# esp8266 register map
File version: 1.0
CPU: Xtensa LX106 1, little endian, no MPU, FPU, 3 interrupt priority bits
Registers are 32-bit, read-write, reset 0x0 unless marked. A register's access mark holds for its fields unless they carry their own. Offsets are from the block's base; lines under a group give offsets from that group; [hi:lo] are bit positions; {n}, {i} and the like mark numbered series; 'fields as' and 'values as' point back to an identical list; <NAME> marks a mode.

## Memory map
0x3FF00000 DPORT size 0xA4
0x3FF00050 EFUSE size 0x80
0x60000000 UART0 size 0x1E0
0x60000100 SPI1 size 0x100
0x60000200 SPI0 size 0x100
0x60000300 GPIO size 0x3A0
0x60000600 TIMER size 0x120
0x60000700 RTC size 0x100
0x60000800 IO_MUX size 0x220
0x60000900 WDT size 0x80
0x60000B00 SLC size 0x400
0x60000E00 I2S size 0x160
0x60000F00 UART1 size 0x1E0

## DPORT
Base 0x3FF00000
0x04 EDGE_INT_ENABLE
  [31:0] Register
0x14 DPORT_CTL
  [0] DPORT_CTL_DOUBLE_CLK

## EFUSE
Base 0x3FF00050
{0x0+4i} EFUSE_DATA{i} (i=0..3)
  [31:0] Register

## GPIO
Base 0x60000300
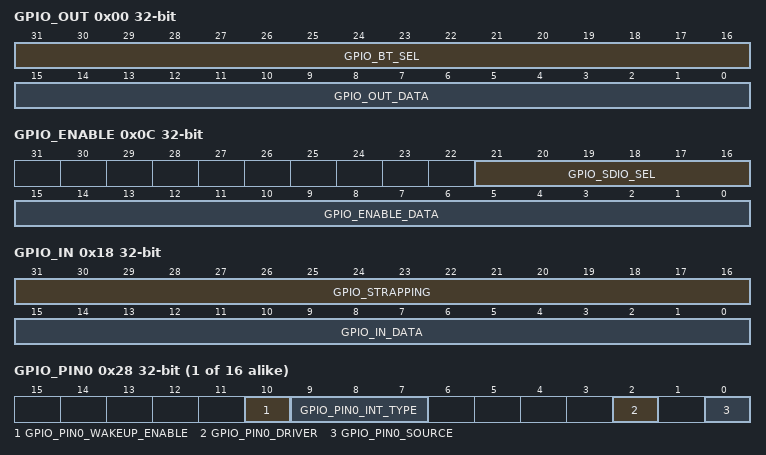
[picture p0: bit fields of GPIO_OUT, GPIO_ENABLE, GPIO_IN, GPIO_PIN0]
0x00 GPIO_OUT — BT-Coexist Selection register
  [31:16] GPIO_BT_SEL — BT-Coexist Selection register
  [15:0] GPIO_OUT_DATA — The output value when the GPIO pin is set as output.
0x04 GPIO_OUT_W1TS wo
  [15:0] GPIO_OUT_DATA_W1TS — Writing 1 into a bit in this register will set the related bit in GPIO_OUT_DATA
0x08 GPIO_OUT_W1TC wo
  [15:0] GPIO_OUT_DATA_W1TC — Writing 1 into a bit in this register will clear the related bit in GPIO_OUT_DATA
0x0C GPIO_ENABLE
  [21:16] GPIO_SDIO_SEL — SDIO-dis selection register
  [15:0] GPIO_ENABLE_DATA — The output enable register.
0x10 GPIO_ENABLE_W1TS wo
  [15:0] GPIO_ENABLE_DATA_W1TS — Writing 1 into a bit in this register will set the related bit in GPIO_ENABLE_DATA
0x14 GPIO_ENABLE_W1TC wo
  [15:0] GPIO_ENABLE_DATA_W1TC — Writing 1 into a bit in this register will clear the related bit in GPIO_ENABLE_DATA
0x18 GPIO_IN — The values of the strapping pins.
  [31:16] GPIO_STRAPPING — The values of the strapping pins.
  [15:0] GPIO_IN_DATA — The values of the GPIO pins when the GPIO pin is set as input.
0x1C GPIO_STATUS
  [15:0] GPIO_STATUS_INTERRUPT — Interrupt enable register.
0x20 GPIO_STATUS_W1TS wo
  [15:0] GPIO_STATUS_INTERRUPT_W1TS — Writing 1 into a bit in this register will set the related bit in GPIO_STATUS_INTERRUPT
0x24 GPIO_STATUS_W1TC wo
  [15:0] GPIO_STATUS_INTERRUPT_W1TC — Writing 1 into a bit in this register will clear the related bit in GPIO_STATUS_INTERRUPT
{0x28+4i} GPIO_PIN{i} (i=0..15)
  [10] GPIO_PIN{i}_WAKEUP_ENABLE — 0: disable; 1: enable GPIO wakeup CPU, only when GPIO_PIN0_INT_TYPE is 0x4 or 0x5
  [9:7] GPIO_PIN{i}_INT_TYPE — 0: disable; 1: positive edge; 2: negative edge; 3: both types of edge; 4: low-level; 5: high-level
  [2] GPIO_PIN{i}_DRIVER — 1: open drain; 0: normal
  [0] GPIO_PIN{i}_SOURCE — 1: sigma-delta; 0: GPIO_DATA
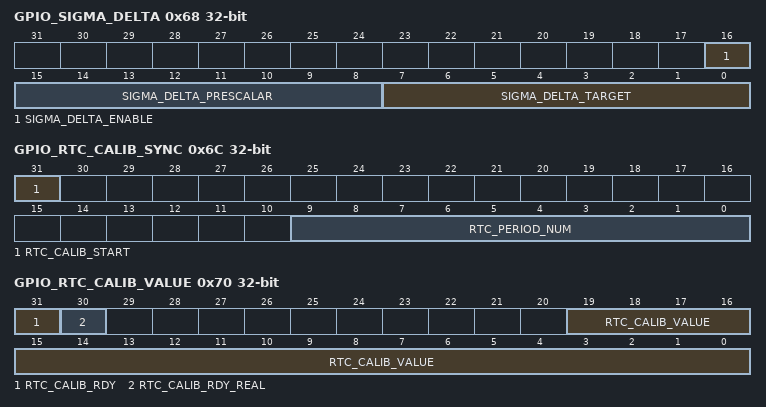
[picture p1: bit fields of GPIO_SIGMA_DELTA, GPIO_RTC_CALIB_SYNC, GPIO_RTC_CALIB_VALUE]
0x68 GPIO_SIGMA_DELTA
  [16] SIGMA_DELTA_ENABLE — 1: enable sigma-delta; 0: disable
  [15:8] SIGMA_DELTA_PRESCALAR — Clock pre-divider for sigma-delta.
  [7:0] SIGMA_DELTA_TARGET — target level of the sigma-delta. It is a signed byte.
0x6C GPIO_RTC_CALIB_SYNC — Positvie edge of this bit will trigger the RTC-clock-calibration process.
  [31] RTC_CALIB_START — Positvie edge of this bit will trigger the RTC-clock-calibration process.
  [9:0] RTC_PERIOD_NUM — The cycle number of RTC-clock during RTC-clock-calibration
0x70 GPIO_RTC_CALIB_VALUE — 0: during RTC-clock-calibration; 1: RTC-clock-calibration is done
  [31] RTC_CALIB_RDY — 0: during RTC-clock-calibration; 1: RTC-clock-calibration is done
  [30] RTC_CALIB_RDY_REAL — 0: during RTC-clock-calibration; 1: RTC-clock-calibration is done
  [19:0] RTC_CALIB_VALUE — The cycle number of clk_xtal (crystal clock) for the RTC_PERIOD_NUM cycles of RTC-clock

## I2S
Base 0x60000E00
0x00 I2STXFIFO
  [31:0] Register
0x04 I2SRXFIFO
  [31:0] Register
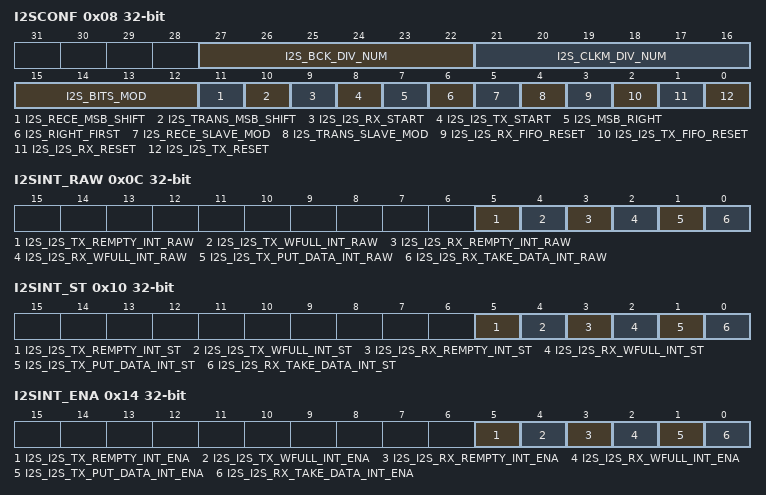
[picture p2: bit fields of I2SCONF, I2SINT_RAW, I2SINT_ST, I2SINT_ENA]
0x08 I2SCONF
  [27:22] I2S_BCK_DIV_NUM, [21:16] I2S_CLKM_DIV_NUM, [15:12] I2S_BITS_MOD, [11] I2S_RECE_MSB_SHIFT, [10] I2S_TRANS_MSB_SHIFT, [9] I2S_I2S_RX_START, [8] I2S_I2S_TX_START, [7] I2S_MSB_RIGHT, [6] I2S_RIGHT_FIRST, [5] I2S_RECE_SLAVE_MOD, [4] I2S_TRANS_SLAVE_MOD, [3] I2S_I2S_RX_FIFO_RESET, [2] I2S_I2S_TX_FIFO_RESET, [1] I2S_I2S_RX_RESET, [0] I2S_I2S_TX_RESET
0x0C I2SINT_RAW
  [5] I2S_I2S_TX_REMPTY_INT_RAW, [4] I2S_I2S_TX_WFULL_INT_RAW, [3] I2S_I2S_RX_REMPTY_INT_RAW, [2] I2S_I2S_RX_WFULL_INT_RAW, [1] I2S_I2S_TX_PUT_DATA_INT_RAW, [0] I2S_I2S_RX_TAKE_DATA_INT_RAW
0x10 I2SINT_ST
  [5] I2S_I2S_TX_REMPTY_INT_ST, [4] I2S_I2S_TX_WFULL_INT_ST, [3] I2S_I2S_RX_REMPTY_INT_ST, [2] I2S_I2S_RX_WFULL_INT_ST, [1] I2S_I2S_TX_PUT_DATA_INT_ST, [0] I2S_I2S_RX_TAKE_DATA_INT_ST
0x14 I2SINT_ENA
  [5] I2S_I2S_TX_REMPTY_INT_ENA, [4] I2S_I2S_TX_WFULL_INT_ENA, [3] I2S_I2S_RX_REMPTY_INT_ENA, [2] I2S_I2S_RX_WFULL_INT_ENA, [1] I2S_I2S_TX_PUT_DATA_INT_ENA, [0] I2S_I2S_RX_TAKE_DATA_INT_ENA
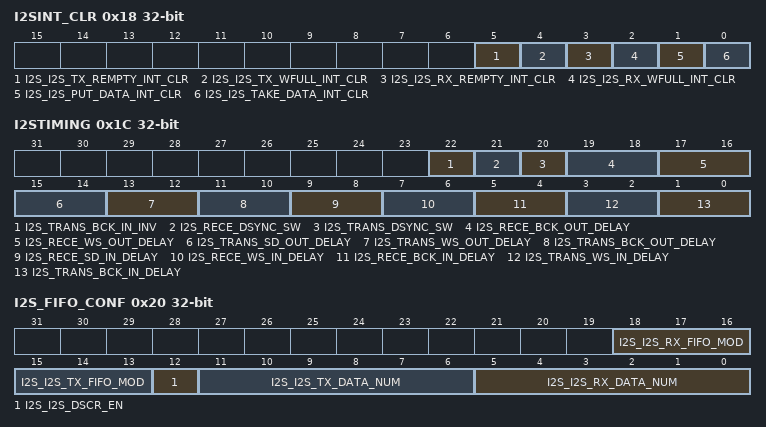
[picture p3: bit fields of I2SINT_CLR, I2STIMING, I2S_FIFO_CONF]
0x18 I2SINT_CLR
  [5] I2S_I2S_TX_REMPTY_INT_CLR, [4] I2S_I2S_TX_WFULL_INT_CLR, [3] I2S_I2S_RX_REMPTY_INT_CLR, [2] I2S_I2S_RX_WFULL_INT_CLR, [1] I2S_I2S_PUT_DATA_INT_CLR, [0] I2S_I2S_TAKE_DATA_INT_CLR
0x1C I2STIMING
  [22] I2S_TRANS_BCK_IN_INV, [21] I2S_RECE_DSYNC_SW, [20] I2S_TRANS_DSYNC_SW, [19:18] I2S_RECE_BCK_OUT_DELAY, [17:16] I2S_RECE_WS_OUT_DELAY, [15:14] I2S_TRANS_SD_OUT_DELAY, [13:12] I2S_TRANS_WS_OUT_DELAY, [11:10] I2S_TRANS_BCK_OUT_DELAY, [9:8] I2S_RECE_SD_IN_DELAY, [7:6] I2S_RECE_WS_IN_DELAY, [5:4] I2S_RECE_BCK_IN_DELAY, [3:2] I2S_TRANS_WS_IN_DELAY, [1:0] I2S_TRANS_BCK_IN_DELAY
0x20 I2S_FIFO_CONF
  [18:16] I2S_I2S_RX_FIFO_MOD, [15:13] I2S_I2S_TX_FIFO_MOD, [12] I2S_I2S_DSCR_EN, [11:6] I2S_I2S_TX_DATA_NUM, [5:0] I2S_I2S_RX_DATA_NUM
0x24 I2SRXEOF_NUM
  [31:0] I2S_I2S_RX_EOF_NUM
0x28 I2SCONF_SIGLE_DATA
  [31:0] I2S_I2S_SIGLE_DATA
